# ESP32-C3 register map
Vendor: ESPRESSIF SYSTEMS (SHANGHAI) CO., LTD.; Series: ESP32 C-Series; File version: 19
CPU: RV32IMC r0p0, little endian, no MPU, no FPU, 0 interrupt priority bits
Address unit: 32 bits
Registers are 32-bit, read-write, reset 0x0 unless marked. A register's access mark holds for its fields unless they carry their own. Offsets are from the block's base; [hi:lo] are bit positions; lines under a group give offsets from that group; {n}, {i} and the like mark numbered series.

## ASSIST_DEBUG — Debug Assist
Base 0x600CE000
{0x0+0x9C*i} CPU{i} (i=0..0) group — Cluster CPU{i}, containing CORE_?_DEBUG_MODE, CORE_?_AREA_DRAM0_0_MAX, CORE_?_AREA_DRAM0_0_MIN, CORE_?_AREA_DRAM0_1_MAX, CORE_?_AREA_DRAM0_1_MIN, CORE_?_AREA_PC, CORE_?_AREA_PIF_0_MAX, CORE_?_AREA_PIF_0_MIN, CORE_?_AREA_PIF_1_MAX, CORE_?_AREA_PIF_1_MIN, CORE_?_AREA_SP, CORE_?_DRAM0_EXCEPTION_MONITOR_0, CORE_?_DRAM0_EXCEPTION_MONITOR_1, CORE_?_DRAM0_EXCEPTION_MONITOR_2, CORE_?_DRAM0_EXCEPTION_MONITOR_3, CORE_?_INTR_CLR, CORE_?_INTR_ENA, CORE_?_INTR_RAW, CORE_?_IRAM0_EXCEPTION_MONITOR_0, CORE_?_IRAM0_EXCEPTION_MONITOR_1, CORE_?_LASTPC_BEFORE_EXCEPTION, CORE_?_MONTR_ENA, CORE_?_RCD_EN, CORE_?_RCD_PDEBUGPC, CORE_?_RCD_PDEBUGSP, CORE_?_SP_MAX, CORE_?_SP_MIN, CORE_?_SP_PC
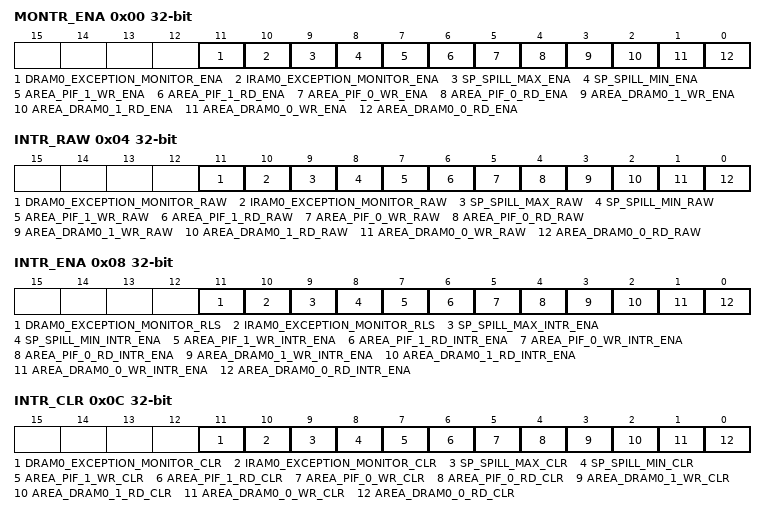
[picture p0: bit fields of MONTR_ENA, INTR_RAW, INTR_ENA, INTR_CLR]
  0x00 MONTR_ENA — ASSIST_DEBUG_CORE_0_MONTR_ENA_REG
    [11] DRAM0_EXCEPTION_MONITOR_ENA — reg_core_0_dram0_exception_monitor_ena
    [10] IRAM0_EXCEPTION_MONITOR_ENA — reg_core_0_iram0_exception_monitor_ena
    [9] SP_SPILL_MAX_ENA — reg_core_0_sp_spill_max_ena
    [8] SP_SPILL_MIN_ENA — reg_core_0_sp_spill_min_ena
    [7] AREA_PIF_1_WR_ENA — reg_core_0_area_pif_1_wr_ena
    [6] AREA_PIF_1_RD_ENA — reg_core_0_area_pif_1_rd_ena
    [5] AREA_PIF_0_WR_ENA — reg_core_0_area_pif_0_wr_ena
    [4] AREA_PIF_0_RD_ENA — reg_core_0_area_pif_0_rd_ena
    [3] AREA_DRAM0_1_WR_ENA — reg_core_0_area_dram0_1_wr_ena
    [2] AREA_DRAM0_1_RD_ENA — reg_core_0_area_dram0_1_rd_ena
    [1] AREA_DRAM0_0_WR_ENA — reg_core_0_area_dram0_0_wr_ena
    [0] AREA_DRAM0_0_RD_ENA — reg_core_0_area_dram0_0_rd_ena
  0x04 INTR_RAW ro — ASSIST_DEBUG_CORE_0_INTR_RAW_REG
    [11] DRAM0_EXCEPTION_MONITOR_RAW — reg_core_0_dram0_exception_monitor_raw
    [10] IRAM0_EXCEPTION_MONITOR_RAW — reg_core_0_iram0_exception_monitor_raw
    [9] SP_SPILL_MAX_RAW — reg_core_0_sp_spill_max_raw
    [8] SP_SPILL_MIN_RAW — reg_core_0_sp_spill_min_raw
    [7] AREA_PIF_1_WR_RAW — reg_core_0_area_pif_1_wr_raw
    [6] AREA_PIF_1_RD_RAW — reg_core_0_area_pif_1_rd_raw
    [5] AREA_PIF_0_WR_RAW — reg_core_0_area_pif_0_wr_raw
    [4] AREA_PIF_0_RD_RAW — reg_core_0_area_pif_0_rd_raw
    [3] AREA_DRAM0_1_WR_RAW — reg_core_0_area_dram0_1_wr_raw
    [2] AREA_DRAM0_1_RD_RAW — reg_core_0_area_dram0_1_rd_raw
    [1] AREA_DRAM0_0_WR_RAW — reg_core_0_area_dram0_0_wr_raw
    [0] AREA_DRAM0_0_RD_RAW — reg_core_0_area_dram0_0_rd_raw
  0x08 INTR_ENA — ASSIST_DEBUG_CORE_0_INTR_ENA_REG
    [11] DRAM0_EXCEPTION_MONITOR_RLS — reg_core_0_dram0_exception_monitor_ena
    [10] IRAM0_EXCEPTION_MONITOR_RLS — reg_core_0_iram0_exception_monitor_ena
    [9] SP_SPILL_MAX_INTR_ENA — reg_core_0_sp_spill_max_intr_ena
    [8] SP_SPILL_MIN_INTR_ENA — reg_core_0_sp_spill_min_intr_ena
    [7] AREA_PIF_1_WR_INTR_ENA — reg_core_0_area_pif_1_wr_intr_ena
    [6] AREA_PIF_1_RD_INTR_ENA — reg_core_0_area_pif_1_rd_intr_ena
    [5] AREA_PIF_0_WR_INTR_ENA — reg_core_0_area_pif_0_wr_intr_ena
    [4] AREA_PIF_0_RD_INTR_ENA — reg_core_0_area_pif_0_rd_intr_ena
    [3] AREA_DRAM0_1_WR_INTR_ENA — reg_core_0_area_dram0_1_wr_intr_ena
    [2] AREA_DRAM0_1_RD_INTR_ENA — reg_core_0_area_dram0_1_rd_intr_ena
    [1] AREA_DRAM0_0_WR_INTR_ENA — reg_core_0_area_dram0_0_wr_intr_ena
    [0] AREA_DRAM0_0_RD_INTR_ENA — reg_core_0_area_dram0_0_rd_intr_ena
  0x0C INTR_CLR — ASSIST_DEBUG_CORE_0_INTR_CLR_REG
    [11] DRAM0_EXCEPTION_MONITOR_CLR — reg_core_0_dram0_exception_monitor_clr
    [10] IRAM0_EXCEPTION_MONITOR_CLR — reg_core_0_iram0_exception_monitor_clr
    [9] SP_SPILL_MAX_CLR — reg_core_0_sp_spill_max_clr
    [8] SP_SPILL_MIN_CLR — reg_core_0_sp_spill_min_clr
    [7] AREA_PIF_1_WR_CLR — reg_core_0_area_pif_1_wr_clr
    [6] AREA_PIF_1_RD_CLR — reg_core_0_area_pif_1_rd_clr
    [5] AREA_PIF_0_WR_CLR — reg_core_0_area_pif_0_wr_clr
    [4] AREA_PIF_0_RD_CLR — reg_core_0_area_pif_0_rd_clr
    [3] AREA_DRAM0_1_WR_CLR — reg_core_0_area_dram0_1_wr_clr
    [2] AREA_DRAM0_1_RD_CLR — reg_core_0_area_dram0_1_rd_clr
    [1] AREA_DRAM0_0_WR_CLR — reg_core_0_area_dram0_0_wr_clr
    [0] AREA_DRAM0_0_RD_CLR — reg_core_0_area_dram0_0_rd_clr
  0x10 AREA_DRAM0_0_MIN reset 0xFFFFFFFF — ASSIST_DEBUG_CORE_0_AREA_DRAM0_0_MIN_REG
    [31:0] AREA_DRAM0_0_MIN — reg_core_0_area_dram0_0_min
  0x14 AREA_DRAM0_0_MAX — ASSIST_DEBUG_CORE_0_AREA_DRAM0_0_MAX_REG
    [31:0] AREA_DRAM0_0_MAX — reg_core_0_area_dram0_0_max
  0x18 AREA_DRAM0_1_MIN reset 0xFFFFFFFF — ASSIST_DEBUG_CORE_0_AREA_DRAM0_1_MIN_REG
    [31:0] AREA_DRAM0_1_MIN — reg_core_0_area_dram0_1_min
  0x1C AREA_DRAM0_1_MAX — ASSIST_DEBUG_CORE_0_AREA_DRAM0_1_MAX_REG
    [31:0] AREA_DRAM0_1_MAX — reg_core_0_area_dram0_1_max
  0x20 AREA_PIF_0_MIN reset 0xFFFFFFFF — ASSIST_DEBUG_CORE_0_AREA_PIF_0_MIN_REG
    [31:0] AREA_PIF_0_MIN — reg_core_0_area_pif_0_min
  0x24 AREA_PIF_0_MAX — ASSIST_DEBUG_CORE_0_AREA_PIF_0_MAX_REG
    [31:0] AREA_PIF_0_MAX — reg_core_0_area_pif_0_max
  0x28 AREA_PIF_1_MIN reset 0xFFFFFFFF — ASSIST_DEBUG_CORE_0_AREA_PIF_1_MIN_REG
    [31:0] AREA_PIF_1_MIN — reg_core_0_area_pif_1_min
  0x2C AREA_PIF_1_MAX — ASSIST_DEBUG_CORE_0_AREA_PIF_1_MAX_REG
    [31:0] AREA_PIF_1_MAX — reg_core_0_area_pif_1_max
  0x30 AREA_PC ro — ASSIST_DEBUG_CORE_0_AREA_PC_REG
    [31:0] AREA_PC — reg_core_0_area_pc
  0x34 AREA_SP ro — ASSIST_DEBUG_CORE_0_AREA_SP_REG
    [31:0] AREA_SP — reg_core_0_area_sp
  0x38 SP_MIN — ASSIST_DEBUG_CORE_0_SP_MIN_REG
    [31:0] SP_MIN — reg_core_0_sp_min
  0x3C SP_MAX reset 0xFFFFFFFF — ASSIST_DEBUG_CORE_0_SP_MAX_REG
    [31:0] SP_MAX — reg_core_0_sp_max
  0x40 SP_PC ro — ASSIST_DEBUG_CORE_0_SP_PC_REG
    [31:0] SP_PC — reg_core_0_sp_pc
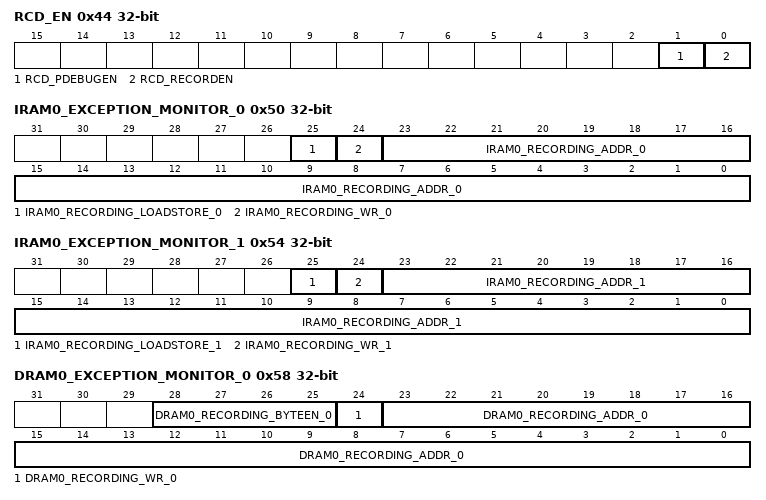
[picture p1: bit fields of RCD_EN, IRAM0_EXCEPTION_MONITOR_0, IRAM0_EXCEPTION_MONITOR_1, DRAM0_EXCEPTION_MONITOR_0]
  0x44 RCD_EN — ASSIST_DEBUG_CORE_0_RCD_EN_REG
    [1] RCD_PDEBUGEN — reg_core_0_rcd_pdebugen
    [0] RCD_RECORDEN — reg_core_0_rcd_recorden
  0x48 RCD_PDEBUGPC ro — ASSIST_DEBUG_CORE_0_RCD_PDEBUGPC_REG
    [31:0] RCD_PDEBUGPC — reg_core_0_rcd_pdebugpc
  0x4C RCD_PDEBUGSP ro — ASSIST_DEBUG_CORE_0_RCD_PDEBUGSP_REG
    [31:0] RCD_PDEBUGSP — reg_core_0_rcd_pdebugsp
  0x50 IRAM0_EXCEPTION_MONITOR_0 ro — ASSIST_DEBUG_CORE_0_RCD_PDEBUGSP_REG
    [25] IRAM0_RECORDING_LOADSTORE_0 — reg_core_0_iram0_recording_loadstore_0
    [24] IRAM0_RECORDING_WR_0 — reg_core_0_iram0_recording_wr_0
    [23:0] IRAM0_RECORDING_ADDR_0 — reg_core_0_iram0_recording_addr_0
  0x54 IRAM0_EXCEPTION_MONITOR_1 ro — ASSIST_DEBUG_CORE_0_IRAM0_EXCEPTION_MONITOR_1_REG
    [25] IRAM0_RECORDING_LOADSTORE_1 — reg_core_0_iram0_recording_loadstore_1
    [24] IRAM0_RECORDING_WR_1 — reg_core_0_iram0_recording_wr_1
    [23:0] IRAM0_RECORDING_ADDR_1 — reg_core_0_iram0_recording_addr_1
  0x58 DRAM0_EXCEPTION_MONITOR_0 ro — ASSIST_DEBUG_CORE_0_DRAM0_EXCEPTION_MONITOR_0_REG
    [28:25] DRAM0_RECORDING_BYTEEN_0 — reg_core_0_dram0_recording_byteen_0
    [24] DRAM0_RECORDING_WR_0 — reg_core_0_dram0_recording_wr_0
    [23:0] DRAM0_RECORDING_ADDR_0 — reg_core_0_dram0_recording_addr_0
  0x5C DRAM0_EXCEPTION_MONITOR_1 ro — ASSIST_DEBUG_CORE_0_DRAM0_EXCEPTION_MONITOR_1_REG
    [31:0] DRAM0_RECORDING_PC_0 — reg_core_0_dram0_recording_pc_0
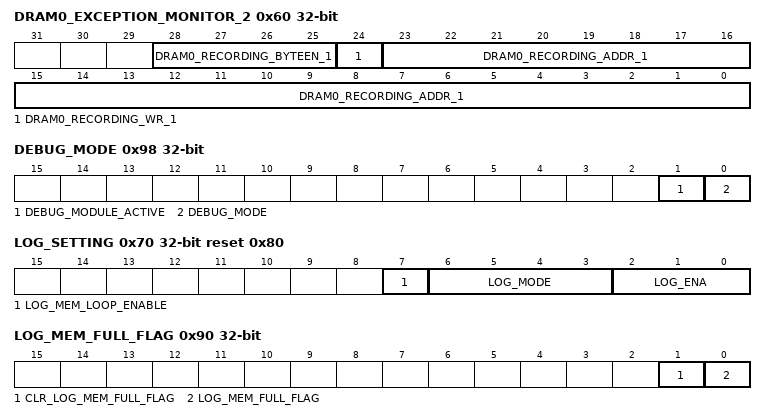
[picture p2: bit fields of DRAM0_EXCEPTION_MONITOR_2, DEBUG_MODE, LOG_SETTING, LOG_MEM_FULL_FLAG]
  0x60 DRAM0_EXCEPTION_MONITOR_2 ro — ASSIST_DEBUG_CORE_0_DRAM0_EXCEPTION_MONITOR_1_REG
    [28:25] DRAM0_RECORDING_BYTEEN_1 — reg_core_0_dram0_recording_byteen_1
    [24] DRAM0_RECORDING_WR_1 — reg_core_0_dram0_recording_wr_1
    [23:0] DRAM0_RECORDING_ADDR_1 — reg_core_0_dram0_recording_addr_1
  0x64 DRAM0_EXCEPTION_MONITOR_3 ro — ASSIST_DEBUG_CORE_0_DRAM0_EXCEPTION_MONITOR_3_REG
    [31:0] DRAM0_RECORDING_PC_1 — reg_core_0_dram0_recording_pc_1
  0x94 LASTPC_BEFORE_EXCEPTION ro — ASSIST_DEBUG_CORE_0_LASTPC_BEFORE_EXCEPTION
    [31:0] LASTPC_BEFORE_EXC — reg_core_0_lastpc_before_exc
  0x98 DEBUG_MODE ro — ASSIST_DEBUG_CORE_0_DEBUG_MODE
    [1] DEBUG_MODULE_ACTIVE — reg_core_0_debug_module_active
    [0] DEBUG_MODE — reg_core_0_debug_mode
{0x68+4i} CORE_X_IRAM0_DRAM0_EXCEPTION_MONITOR{i} (i=0..1) — `¯\_(ツ)_/¯`
  [19:0] LIMIT_CYCLE_0 — reg_core_x_iram0_dram0_limit_cycle_0
0x70 LOG_SETTING reset 0x80 — ASSIST_DEBUG_LOG_SETTING
  [7] LOG_MEM_LOOP_ENABLE — reg_log_mem_loop_enable
  [6:3] LOG_MODE — reg_log_mode
  [2:0] LOG_ENA — reg_log_ena
0x74 LOG_DATA_0 — ASSIST_DEBUG_LOG_DATA_0_REG
  [31:0] LOG_DATA_0 — reg_log_data_0
0x78 LOG_DATA_MASK — ASSIST_DEBUG_LOG_DATA_MASK_REG
  [15:0] LOG_DATA_SIZE — reg_log_data_size
0x7C LOG_MIN — ASSIST_DEBUG_LOG_MIN_REG
  [31:0] LOG_MIN — reg_log_min
0x80 LOG_MAX — ASSIST_DEBUG_LOG_MAX_REG
  [31:0] LOG_MAX — reg_log_max
0x84 LOG_MEM_START — ASSIST_DEBUG_LOG_MEM_START_REG
  [31:0] LOG_MEM_START — reg_log_mem_start
0x88 LOG_MEM_END — ASSIST_DEBUG_LOG_MEM_END_REG
  [31:0] LOG_MEM_END — reg_log_mem_end
0x8C LOG_MEM_WRITING_ADDR ro — ASSIST_DEBUG_LOG_MEM_WRITING_ADDR_REG
  [31:0] LOG_MEM_WRITING_ADDR — reg_log_mem_writing_addr
0x90 LOG_MEM_FULL_FLAG access per field — ASSIST_DEBUG_LOG_MEM_FULL_FLAG_REG
  [1] CLR_LOG_MEM_FULL_FLAG rw — reg_clr_log_mem_full_flag
  [0] LOG_MEM_FULL_FLAG ro — reg_log_mem_full_flag
0x1FC DATE — ASSIST_DEBUG_DATE_REG
